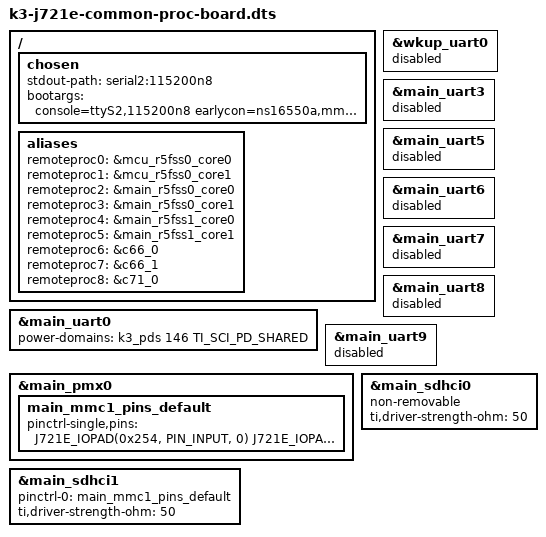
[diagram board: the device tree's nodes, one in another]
// SPDX-License-Identifier: GPL-2.0
/*
 * Copyright (C) 2019 Texas Instruments Incorporated - http://www.ti.com/
 */

/dts-v1/;

#include "k3-j721e-som-p0.dtsi"

/ {
	chosen {
		stdout-path = "serial2:115200n8";
		bootargs = "console=ttyS2,115200n8 earlycon=ns16550a,mmio32,0x02800000";
	};

	aliases {
		remoteproc0 = &mcu_r5fss0_core0;
		remoteproc1 = &mcu_r5fss0_core1;
		remoteproc2 = &main_r5fss0_core0;
		remoteproc3 = &main_r5fss0_core1;
		remoteproc4 = &main_r5fss1_core0;
		remoteproc5 = &main_r5fss1_core1;
		remoteproc6 = &c66_0;
		remoteproc7 = &c66_1;
		remoteproc8 = &c71_0;
	};
};

&wkup_uart0 {
	/* Wakeup UART is used by System firmware */
	status = "disabled";
};

&main_uart0 {
	power-domains = <&k3_pds 146 TI_SCI_PD_SHARED>;
};

&main_uart3 {
	/* UART not brought out */
	status = "disabled";
};

&main_uart5 {
	/* UART not brought out */
	status = "disabled";
};

&main_uart6 {
	/* UART not brought out */
	status = "disabled";
};

&main_uart7 {
	/* UART not brought out */
	status = "disabled";
};

&main_uart8 {
	/* UART not brought out */
	status = "disabled";
};

&main_uart9 {
	/* UART not brought out */
	status = "disabled";
};

&main_pmx0 {
	main_mmc1_pins_default: main_mmc1_pins_default {
		pinctrl-single,pins = <
			J721E_IOPAD(0x254, PIN_INPUT, 0) /* (R29) MMC1_CMD */
			J721E_IOPAD(0x250, PIN_INPUT, 0) /* (P25) MMC1_CLK */
			J721E_IOPAD(0x2ac, PIN_INPUT, 0) /* (P25) MMC1_CLKLB */
			J721E_IOPAD(0x24c, PIN_INPUT, 0) /* (R24) MMC1_DAT0 */
			J721E_IOPAD(0x248, PIN_INPUT, 0) /* (P24) MMC1_DAT1 */
			J721E_IOPAD(0x244, PIN_INPUT, 0) /* (R25) MMC1_DAT2 */
			J721E_IOPAD(0x240, PIN_INPUT, 0) /* (R26) MMC1_DAT3 */
			J721E_IOPAD(0x258, PIN_INPUT, 0) /* (P23) MMC1_SDCD */
			J721E_IOPAD(0x25c, PIN_INPUT, 0) /* (R28) MMC1_SDWP */
		>;
	};
};

&main_sdhci0 {
	/* eMMC */
	non-removable;
	ti,driver-strength-ohm = <50>;
};

&main_sdhci1 {
	/* SD card */
	pinctrl-names = "default";
	pinctrl-0 = <&main_mmc1_pins_default>;
	ti,driver-strength-ohm = <50>;
};
